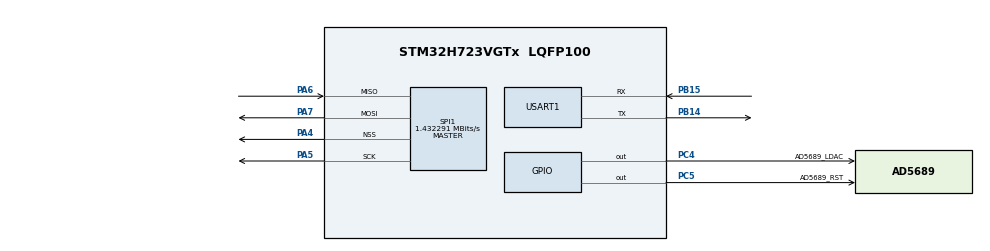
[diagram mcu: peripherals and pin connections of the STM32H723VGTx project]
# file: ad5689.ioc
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Mcu.Family=STM32H7
Mcu.Name=STM32H723VGTx
Mcu.Package=LQFP100
NVIC.PriorityGroup=NVIC_PRIORITYGROUP_4
PA4.Mode=NSS_Signal_Hard_Output
PA4.Signal=SPI1_NSS
PA5.Mode=Full_Duplex_Master
PA5.Signal=SPI1_SCK
PA6.Mode=Full_Duplex_Master
PA6.Signal=SPI1_MISO
PA7.Mode=Full_Duplex_Master
PA7.Signal=SPI1_MOSI
PB14.Mode=Asynchronous
PB14.Signal=USART1_TX
PB15.Mode=Asynchronous
PB15.Signal=USART1_RX
PC14-OSC32_IN.Mode=LSE-External-Oscillator
PC14-OSC32_IN.Signal=RCC_OSC32_IN
PC15-OSC32_OUT.Mode=LSE-External-Oscillator
PC15-OSC32_OUT.Signal=RCC_OSC32_OUT
PC4.GPIO_Label=AD5689_LDAC
PC4.Signal=GPIO_Output
PC5.GPIO_Label=AD5689_RST
PC5.Signal=GPIO_Output
PH0-OSC_IN.Mode=HSE-External-Oscillator
PH0-OSC_IN.Signal=RCC_OSC_IN
PH1-OSC_OUT.Mode=HSE-External-Oscillator
PH1-OSC_OUT.Signal=RCC_OSC_OUT
ProjectManager.HeapSize=0x200
ProjectManager.StackSize=0x400
ProjectManager.TargetToolchain=Makefile
RCC.ADCFreq_Value=50390625
RCC.APB1Freq_Value=137500000
RCC.APB2Freq_Value=137500000
RCC.APB3Freq_Value=137500000
RCC.APB4Freq_Value=137500000
RCC.CortexFreq_Value=550000000
RCC.D1PPRE=RCC_APB3_DIV2
RCC.D2PPRE1=RCC_APB1_DIV2
RCC.D2PPRE2=RCC_APB2_DIV2
RCC.D3PPRE=RCC_APB4_DIV2
RCC.DIVM1=2
RCC.DIVN1=44
RCC.DIVP1=1
RCC.DIVQ1=3
RCC.EnbaleCSS=true
RCC.HCLKFreq_Value=275000000
RCC.HPRE=RCC_HCLK_DIV2
RCC.PLLFRACN=0
RCC.PLLSourceVirtual=RCC_PLLSOURCE_HSE
RCC.SYSCLKFreq_VALUE=550000000
RCC.SYSCLKSource=RCC_SYSCLKSOURCE_PLLCLK
RCC.USBFreq_Value=183333333.33333334
SPI1.BaudRatePrescaler=SPI_BAUDRATEPRESCALER_128
SPI1.CalculateBaudRate=1.432291 MBits/s
SPI1.Direction=SPI_DIRECTION_2LINES
SPI1.Mode=SPI_MODE_MASTER
SPI1.VirtualNSS=VM_NSSHARD
SPI1.VirtualType=VM_MASTER
USART1.VirtualMode-Asynchronous=VM_ASYNC
board=custom

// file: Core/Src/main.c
/* USER CODE BEGIN Header */
/**
 ******************************************************************************
 * @file           : main.c
 * @brief          : Main program body
 ******************************************************************************
 * @attention
 *
 * Copyright (c) 2023 STMicroelectronics.
 * All rights reserved.
 *
 * This software is licensed under terms that can be found in the LICENSE file
 * in the root directory of this software component.
 * If no LICENSE file comes with this software, it is provided AS-IS.
 *
 ******************************************************************************
 */
/* USER CODE END Header */
#include "main.h"
#include "spi.h"
#include "usart.h"
#include "gpio.h"

void SystemClock_Config(void);

/* USER CODE BEGIN 0 */
int _write(int file, char *ptr, int len)
{
  HAL_UART_Transmit(&huart1, (const uint8_t *)ptr, len, HAL_MAX_DELAY);
  return len;
}
/* USER CODE END 0 */

int main(void)
{

  /* MCU Configuration--------------------------------------------------------*/

  /* Reset of all peripherals, Initializes the Flash interface and the Systick. */
  HAL_Init();

  /* Configure the system clock */
  SystemClock_Config();

  /* Initialize all configured peripherals */
  MX_GPIO_Init();
  MX_SPI1_Init();
  MX_USART1_UART_Init();
  /* USER CODE BEGIN 2 */

  ad5689_init(&hspi1, AD5689_LDAC_GPIO_Port, AD5689_LDAC_Pin, AD5689_RST_GPIO_Port, AD5689_RST_Pin);

  /* USER CODE END 2 */

  /* Infinite loop */
  /* USER CODE BEGIN WHILE */
  uint16_t dac_value = 0;
  while (1)
  {
    /* USER CODE END WHILE */

    /* USER CODE BEGIN 3 */
    ad5689_set_dac(dac_value, AD5689_DAC_CH_A_ADDR, 1, 1);
    ++dac_value;
  }
  /* USER CODE END 3 */
}

void SystemClock_Config(void)
{
  RCC_OscInitTypeDef RCC_OscInitStruct = {0};
  RCC_ClkInitTypeDef RCC_ClkInitStruct = {0};

  /** Supply configuration update enable
  */
  HAL_PWREx_ConfigSupply(PWR_LDO_SUPPLY);

  /** Configure the main internal regulator output voltage
  */
  __HAL_PWR_VOLTAGESCALING_CONFIG(PWR_REGULATOR_VOLTAGE_SCALE0);

  while(!__HAL_PWR_GET_FLAG(PWR_FLAG_VOSRDY)) {}

  /** Initializes the RCC Oscillators according to the specified parameters
  * in the RCC_OscInitTypeDef structure.
  */
  RCC_OscInitStruct.OscillatorType = RCC_OSCILLATORTYPE_HSE;
  RCC_OscInitStruct.HSEState = RCC_HSE_ON;
  RCC_OscInitStruct.PLL.PLLState = RCC_PLL_ON;
  RCC_OscInitStruct.PLL.PLLSource = RCC_PLLSOURCE_HSE;
  RCC_OscInitStruct.PLL.PLLM = 2;
  RCC_OscInitStruct.PLL.PLLN = 44;
  RCC_OscInitStruct.PLL.PLLP = 1;
  RCC_OscInitStruct.PLL.PLLQ = 3;
  RCC_OscInitStruct.PLL.PLLR = 2;
  RCC_OscInitStruct.PLL.PLLRGE = RCC_PLL1VCIRANGE_3;
  RCC_OscInitStruct.PLL.PLLVCOSEL = RCC_PLL1VCOWIDE;
  RCC_OscInitStruct.PLL.PLLFRACN = 0;
  if (HAL_RCC_OscConfig(&RCC_OscInitStruct) != HAL_OK)
  {
    Error_Handler();
  }

  /** Initializes the CPU, AHB and APB buses clocks
  */
  RCC_ClkInitStruct.ClockType = RCC_CLOCKTYPE_HCLK|RCC_CLOCKTYPE_SYSCLK
                              |RCC_CLOCKTYPE_PCLK1|RCC_CLOCKTYPE_PCLK2
                              |RCC_CLOCKTYPE_D3PCLK1|RCC_CLOCKTYPE_D1PCLK1;
  RCC_ClkInitStruct.SYSCLKSource = RCC_SYSCLKSOURCE_PLLCLK;
  RCC_ClkInitStruct.SYSCLKDivider = RCC_SYSCLK_DIV1;
  RCC_ClkInitStruct.AHBCLKDivider = RCC_HCLK_DIV2;
  RCC_ClkInitStruct.APB3CLKDivider = RCC_APB3_DIV2;
  RCC_ClkInitStruct.APB1CLKDivider = RCC_APB1_DIV2;
  RCC_ClkInitStruct.APB2CLKDivider = RCC_APB2_DIV2;
  RCC_ClkInitStruct.APB4CLKDivider = RCC_APB4_DIV2;

  if (HAL_RCC_ClockConfig(&RCC_ClkInitStruct, FLASH_LATENCY_3) != HAL_OK)
  {
    Error_Handler();
  }

  /** Enables the Clock Security System
  */
  HAL_RCC_EnableCSS();
}

void Error_Handler(void)
{
  __disable_irq();
  while (1)
  {
  }
}
